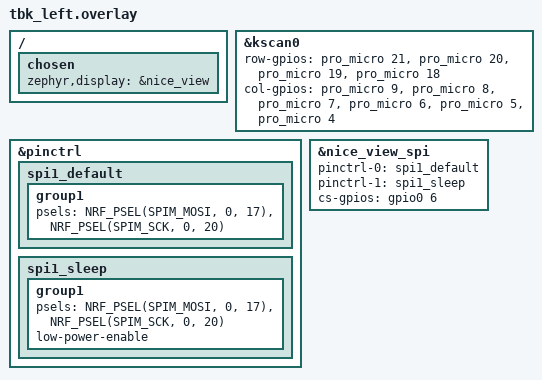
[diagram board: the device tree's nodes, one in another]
#include "tbk.dtsi"

&kscan0 {
    row-gpios
        = <&pro_micro 21 (GPIO_ACTIVE_HIGH | GPIO_PULL_DOWN)>
        , <&pro_micro 20 (GPIO_ACTIVE_HIGH | GPIO_PULL_DOWN)>
        , <&pro_micro 19 (GPIO_ACTIVE_HIGH | GPIO_PULL_DOWN)>
        , <&pro_micro 18 (GPIO_ACTIVE_HIGH | GPIO_PULL_DOWN)>
        ;
    col-gpios
        = <&pro_micro 9 GPIO_ACTIVE_HIGH>
        , <&pro_micro 8 GPIO_ACTIVE_HIGH>
        , <&pro_micro 7 GPIO_ACTIVE_HIGH>
        , <&pro_micro 6 GPIO_ACTIVE_HIGH>
        , <&pro_micro 5 GPIO_ACTIVE_HIGH>
        , <&pro_micro 4 GPIO_ACTIVE_HIGH>
        ;
};

// ── Nice!View Display ──────────────────────────────────────────────
// Wired to: D2 (MOSI=P0.17), D3 (SCK=P0.20), D1 (CS=P0.06)

&pinctrl {
    spi1_default: spi1_default {
        group1 {
            psels = <NRF_PSEL(SPIM_MOSI, 0, 17)>,
                    <NRF_PSEL(SPIM_SCK,  0, 20)>;
        };
    };
    spi1_sleep: spi1_sleep {
        group1 {
            psels = <NRF_PSEL(SPIM_MOSI, 0, 17)>,
                    <NRF_PSEL(SPIM_SCK,  0, 20)>;
            low-power-enable;
        };
    };
};

&nice_view_spi {
    pinctrl-0 = <&spi1_default>;
    pinctrl-1 = <&spi1_sleep>;
    pinctrl-names = "default", "sleep";
    cs-gpios = <&gpio0 6 GPIO_ACTIVE_HIGH>;  /* D1 */
};

/ {
    chosen {
        zephyr,display = &nice_view;
    };
};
